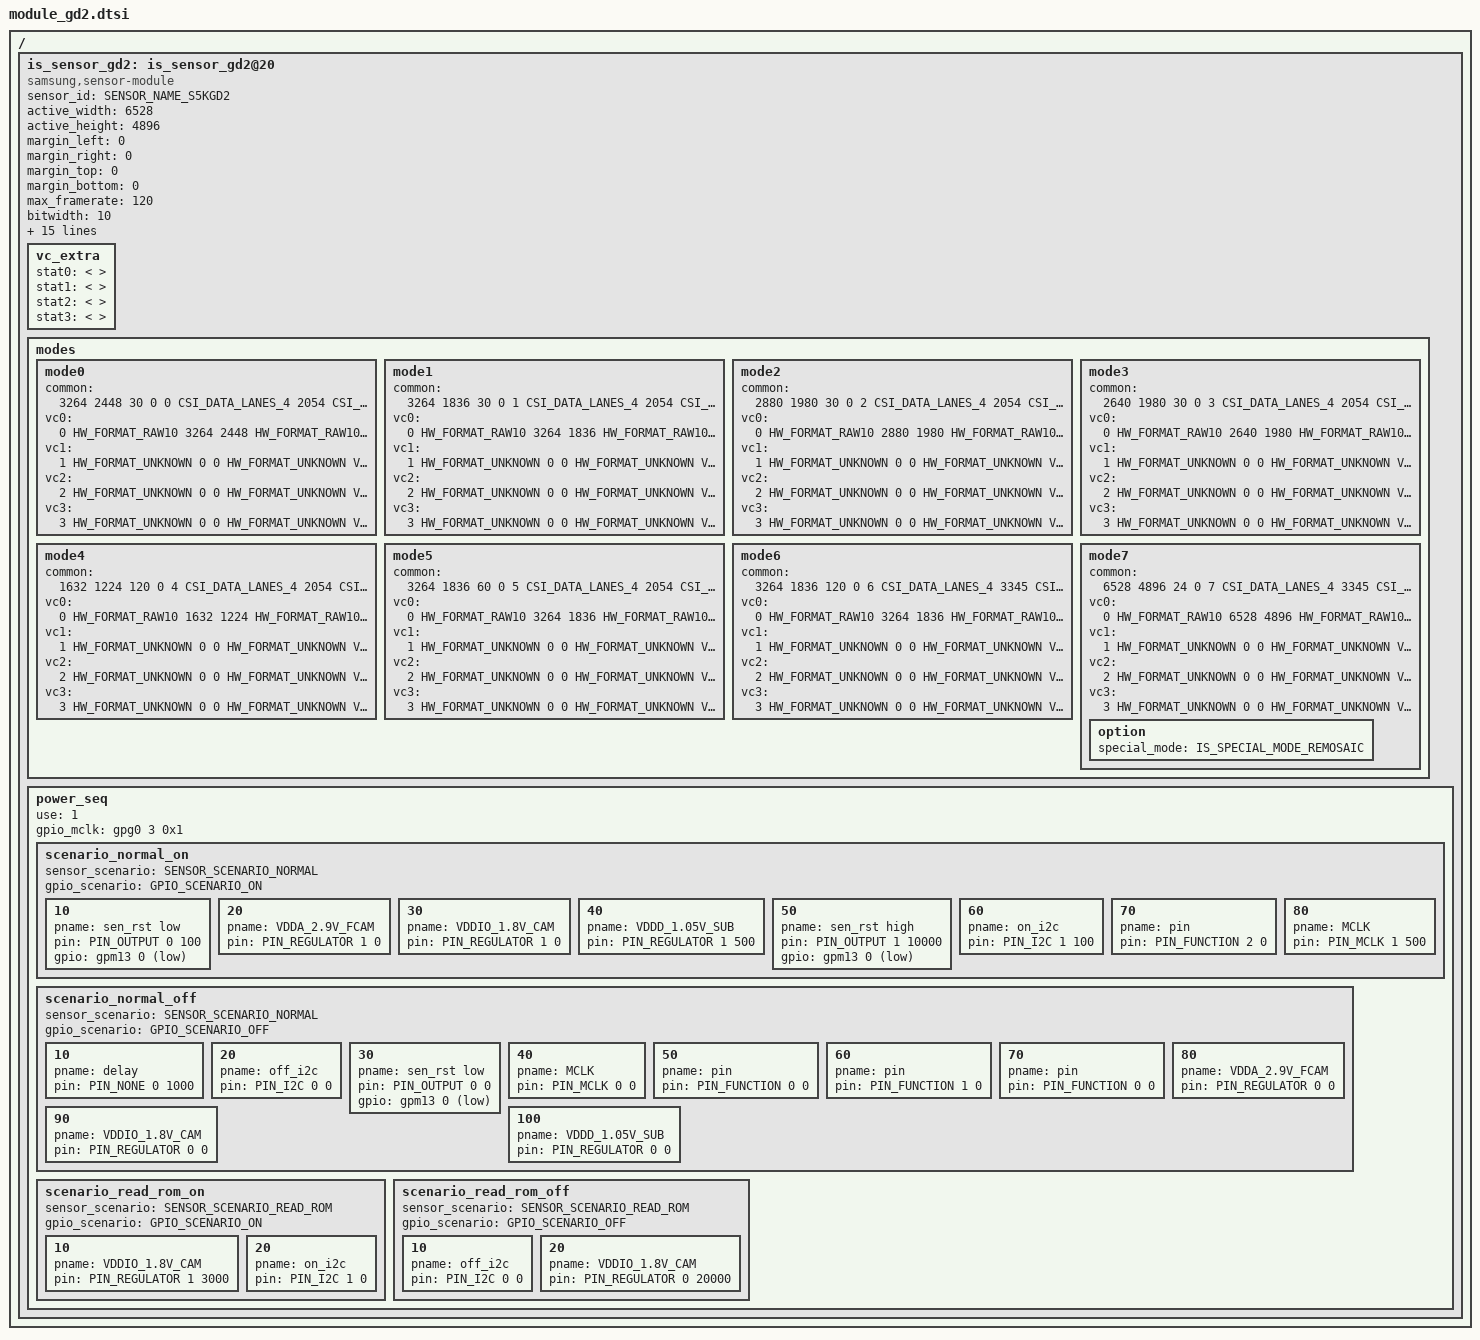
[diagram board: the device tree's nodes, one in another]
/*
 * SAMSUNG EXYNOSxxxx board camera device tree source
 *
 * Copyright (c) 2021 Samsung Electronics Co., Ltd.
 *		http://www.samsung.com
 *
 * This program is free software; you can redistribute it and/or modify
 * it under the terms of the GNU General Public License version 2 as
 * published by the Free Software Foundation.
 */

#include <dt-bindings/camera/exynos_is_dt.h>

/ {
	fragment@camera {
		target-path = "/";
		__overlay__ {
			is_sensor_gd2: is_sensor_gd2@20 {
				compatible = "samsung,sensor-module";

				/* common */
				sensor_id = <SENSOR_NAME_S5KGD2>;
				active_width = <6528>;
				active_height = <4896>;
				margin_left = <0>;
				margin_right = <0>;
				margin_top = <0>;
				margin_bottom = <0>;
				max_framerate = <120>;
				bitwidth = <10>;
				use_retention_mode = <SENSOR_RETENTION_INACTIVE>;
				sensor_maker = "SONY";
				sensor_name = "S5KGD2";
				setfile_name = "setfile_gd2.bin";

				status = "okay";

				/* board */
				pinctrl-names = "pin0", "pin1", "pin2", "release";
				pinctrl-0 = <>;
				pinctrl-1 = <&sensor_mclk1_out>;
				pinctrl-2 = <&sensor_mclk1_fn>;
				pinctrl-3 = <>;

				position = <1>;	/* Rear:0. Front:1. Rear_sub:2. Secure:3. */
				id = <1>; /* is_sensor id */
				mclk_ch = <1>;
				sensor_i2c_ch = <5>; /* SENSOR_CONTROL_I2C4 */

				/* vendor */
				rom_type = <2>; /* ROM_TYPE_EEPROM */
				rom_id = <1>;
				rom_cal_index = <0>;

				vc_extra {
					/* ex) statX = <stat_type, sensor_mode, max_width, max_height, max_element> */
					/* VC_BUF_DATA_TYPE_SENSOR_STAT1 */
					stat0 = </* not available */>;
					/* VC_BUF_DATA_TYPE_GENERAL_STAT1 */
					stat1 = </* not available */>;
					/* VC_BUF_DATA_TYPE_SENSOR_STAT2 */
					stat2 = </* not available */>;
					/* VC_BUF_DATA_TYPE_GENERAL_STAT2 */
					stat3 = </* not available */>;
				};

				/* sensor modes */
				modes {
					/* common = <width, height, fps, settle, mode, lane, speed, interleave, lrte, pd_mode> */
					/* vcX = <map, hwformat, width, height, hwformat, type, width, height> */

					mode0 {
						common = <3264 2448 30 0 0 CSI_DATA_LANES_4 2054 CSI_MODE_DT_ONLY LRTE_DISABLE PD_NONE EX_NONE>;
						vc0 = </* in */ 0 HW_FORMAT_RAW10 3264 2448	/* out */ HW_FORMAT_RAW10 VC_NOTHING 0 0>;
						vc1 = </* in */ 1 HW_FORMAT_UNKNOWN 0 0		/* out */ HW_FORMAT_UNKNOWN VC_NOTHING 0 0>;
						vc2 = </* in */ 2 HW_FORMAT_UNKNOWN 0 0		/* out */ HW_FORMAT_UNKNOWN VC_NOTHING 0 0>;
						vc3 = </* in */ 3 HW_FORMAT_UNKNOWN 0 0		/* out */ HW_FORMAT_UNKNOWN VC_NOTHING 0 0>;
					};
					mode1 {
						common = <3264 1836 30 0 1 CSI_DATA_LANES_4 2054 CSI_MODE_DT_ONLY LRTE_DISABLE PD_NONE EX_NONE>;
						vc0 = </* in */ 0 HW_FORMAT_RAW10 3264 1836	/* out */ HW_FORMAT_RAW10 VC_NOTHING 0 0>;
						vc1 = </* in */ 1 HW_FORMAT_UNKNOWN 0 0		/* out */ HW_FORMAT_UNKNOWN VC_NOTHING 0 0>;
						vc2 = </* in */ 2 HW_FORMAT_UNKNOWN 0 0		/* out */ HW_FORMAT_UNKNOWN VC_NOTHING 0 0>;
						vc3 = </* in */ 3 HW_FORMAT_UNKNOWN 0 0		/* out */ HW_FORMAT_UNKNOWN VC_NOTHING 0 0>;
					};
					mode2 {
						common = <2880 1980 30 0 2 CSI_DATA_LANES_4 2054 CSI_MODE_DT_ONLY LRTE_DISABLE PD_NONE EX_NONE>;
						vc0 = </* in */ 0 HW_FORMAT_RAW10 2880 1980	/* out */ HW_FORMAT_RAW10 VC_NOTHING 0 0>;
						vc1 = </* in */ 1 HW_FORMAT_UNKNOWN 0 0		/* out */ HW_FORMAT_UNKNOWN VC_NOTHING 0 0>;
						vc2 = </* in */ 2 HW_FORMAT_UNKNOWN 0 0		/* out */ HW_FORMAT_UNKNOWN VC_NOTHING 0 0>;
						vc3 = </* in */ 3 HW_FORMAT_UNKNOWN 0 0		/* out */ HW_FORMAT_UNKNOWN VC_NOTHING 0 0>;
					};
					mode3 {
						common = <2640 1980 30 0 3 CSI_DATA_LANES_4 2054 CSI_MODE_DT_ONLY LRTE_DISABLE PD_NONE EX_NONE>;
						vc0 = </* in */ 0 HW_FORMAT_RAW10 2640 1980	/* out */ HW_FORMAT_RAW10 VC_NOTHING 0 0>;
						vc1 = </* in */ 1 HW_FORMAT_UNKNOWN 0 0		/* out */ HW_FORMAT_UNKNOWN VC_NOTHING 0 0>;
						vc2 = </* in */ 2 HW_FORMAT_UNKNOWN 0 0		/* out */ HW_FORMAT_UNKNOWN VC_NOTHING 0 0>;
						vc3 = </* in */ 3 HW_FORMAT_UNKNOWN 0 0		/* out */ HW_FORMAT_UNKNOWN VC_NOTHING 0 0>;
					};
					mode4 {
						common = <1632 1224 120 0 4 CSI_DATA_LANES_4 2054 CSI_MODE_DT_ONLY LRTE_DISABLE PD_NONE EX_NONE>;
						vc0 = </* in */ 0 HW_FORMAT_RAW10 1632 1224	/* out */ HW_FORMAT_RAW10 VC_NOTHING 0 0>;
						vc1 = </* in */ 1 HW_FORMAT_UNKNOWN 0 0		/* out */ HW_FORMAT_UNKNOWN VC_NOTHING 0 0>;
						vc2 = </* in */ 2 HW_FORMAT_UNKNOWN 0 0		/* out */ HW_FORMAT_UNKNOWN VC_NOTHING 0 0>;
						vc3 = </* in */ 3 HW_FORMAT_UNKNOWN 0 0		/* out */ HW_FORMAT_UNKNOWN VC_NOTHING 0 0>;
					};
					mode5 {
						common = <3264 1836 60 0 5 CSI_DATA_LANES_4 2054 CSI_MODE_DT_ONLY LRTE_DISABLE PD_NONE EX_NONE>;
						vc0 = </* in */ 0 HW_FORMAT_RAW10 3264 1836	/* out */ HW_FORMAT_RAW10 VC_NOTHING 0 0>;
						vc1 = </* in */ 1 HW_FORMAT_UNKNOWN 0 0		/* out */ HW_FORMAT_UNKNOWN VC_NOTHING 0 0>;
						vc2 = </* in */ 2 HW_FORMAT_UNKNOWN 0 0		/* out */ HW_FORMAT_UNKNOWN VC_NOTHING 0 0>;
						vc3 = </* in */ 3 HW_FORMAT_UNKNOWN 0 0		/* out */ HW_FORMAT_UNKNOWN VC_NOTHING 0 0>;
					};
					mode6 {
						common = <3264 1836 120 0 6 CSI_DATA_LANES_4 3345 CSI_MODE_DT_ONLY LRTE_DISABLE PD_NONE EX_NONE>;
						vc0 = </* in */ 0 HW_FORMAT_RAW10 3264 1836	/* out */ HW_FORMAT_RAW10 VC_NOTHING 0 0>;
						vc1 = </* in */ 1 HW_FORMAT_UNKNOWN 0 0		/* out */ HW_FORMAT_UNKNOWN VC_NOTHING 0 0>;
						vc2 = </* in */ 2 HW_FORMAT_UNKNOWN 0 0		/* out */ HW_FORMAT_UNKNOWN VC_NOTHING 0 0>;
						vc3 = </* in */ 3 HW_FORMAT_UNKNOWN 0 0		/* out */ HW_FORMAT_UNKNOWN VC_NOTHING 0 0>;
					};
					mode7 {
						common = <6528 4896 24 0 7 CSI_DATA_LANES_4 3345 CSI_MODE_DT_ONLY LRTE_DISABLE PD_NONE EX_NONE>;
						vc0 = </* in */ 0 HW_FORMAT_RAW10 6528 4896	/* out */ HW_FORMAT_RAW10 VC_NOTHING 0 0>;
						vc1 = </* in */ 1 HW_FORMAT_UNKNOWN 0 0		/* out */ HW_FORMAT_UNKNOWN VC_NOTHING 0 0>;
						vc2 = </* in */ 2 HW_FORMAT_UNKNOWN 0 0		/* out */ HW_FORMAT_UNKNOWN VC_NOTHING 0 0>;
						vc3 = </* in */ 3 HW_FORMAT_UNKNOWN 0 0		/* out */ HW_FORMAT_UNKNOWN VC_NOTHING 0 0>;
						option { special_mode = <IS_SPECIAL_MODE_REMOSAIC>; };
					};
				};

				power_seq {
					use = <1>;
					gpio_mclk = <&gpg0 3 0x1>;

					scenario_normal_on {
						
						sensor_scenario = <SENSOR_SCENARIO_NORMAL>;
						gpio_scenario = <GPIO_SCENARIO_ON>;

						/* A start node number should be over the 10 for reserved number 0~9. */
						/* pname = "name"; pin = <act value delay voltage>; gpio = <gpx# # 0x1>; */
						
						10 { pname = "sen_rst low"; pin = <PIN_OUTPUT 0 100>; gpio = <&gpm13 0 0x1>; };
						20 { pname = "VDDA_2.9V_FCAM"; pin = <PIN_REGULATOR 1 0>; };
						30 { pname = "VDDIO_1.8V_CAM"; pin = <PIN_REGULATOR 1 0>; };
						40 { pname = "VDDD_1.05V_SUB"; pin = <PIN_REGULATOR 1 500>; };
						50 { pname = "sen_rst high"; pin = <PIN_OUTPUT 1 10000>; gpio = <&gpm13 0 0x1>; };
						60 { pname = "on_i2c"; pin = <PIN_I2C 1 100>; };
						70 { pname = "pin"; pin = <PIN_FUNCTION 2 0>; };
						80 { pname = "MCLK"; pin = <PIN_MCLK 1 500>; };
					};

					scenario_normal_off {
						sensor_scenario = <SENSOR_SCENARIO_NORMAL>;
						gpio_scenario = <GPIO_SCENARIO_OFF>;


						/* A start node number should be over the 10 for reserved number 0~9. */
						/* pname = "name"; pin = <act value delay voltage>; gpio = <gpx# # 0x1>; */
						
						10 { pname = "delay"; pin = <PIN_NONE 0 1000>; };
						20 { pname = "off_i2c"; pin = <PIN_I2C 0 0>; };
						30 { pname = "sen_rst low"; pin = <PIN_OUTPUT 0 0>; gpio = <&gpm13 0 0x1>; };
						40 { pname = "MCLK"; pin = <PIN_MCLK 0 0>; };
						50 { pname = "pin"; pin = <PIN_FUNCTION 0 0>; };
						60 { pname = "pin"; pin = <PIN_FUNCTION 1 0>; };
						70 { pname = "pin"; pin = <PIN_FUNCTION 0 0>; };
						80 { pname = "VDDA_2.9V_FCAM"; pin = <PIN_REGULATOR 0 0>; };
						90 { pname = "VDDIO_1.8V_CAM"; pin = <PIN_REGULATOR 0 0>; };
						100 { pname = "VDDD_1.05V_SUB"; pin = <PIN_REGULATOR 0 0>; };
					};

					scenario_read_rom_on {
						sensor_scenario = <SENSOR_SCENARIO_READ_ROM>;
						gpio_scenario = <GPIO_SCENARIO_ON>;

						/* A start node number should be over the 10 for reserved number 0~9. */
						/* pname = "name"; pin = <act value delay voltage>; gpio = <gpx# # 0x1>; */
						
						10 { pname = "VDDIO_1.8V_CAM"; pin = <PIN_REGULATOR 1 3000>; };
						20 { pname = "on_i2c"; pin = <PIN_I2C 1 0>; };
					};

					scenario_read_rom_off {
						sensor_scenario = <SENSOR_SCENARIO_READ_ROM>;
						gpio_scenario = <GPIO_SCENARIO_OFF>;

						/* A start node number should be over the 10 for reserved number 0~9. */
						/* pname = "name"; pin = <act value delay voltage>; gpio = <gpx# # 0x1>; */
						
						10 { pname = "off_i2c"; pin = <PIN_I2C 0 0>; };
						20 { pname = "VDDIO_1.8V_CAM"; pin = <PIN_REGULATOR 0 20000>; };
					};
				};
			};
		}; /* end of __overlay__ */
	}; /* end of fragment */
}; /* end of root */
